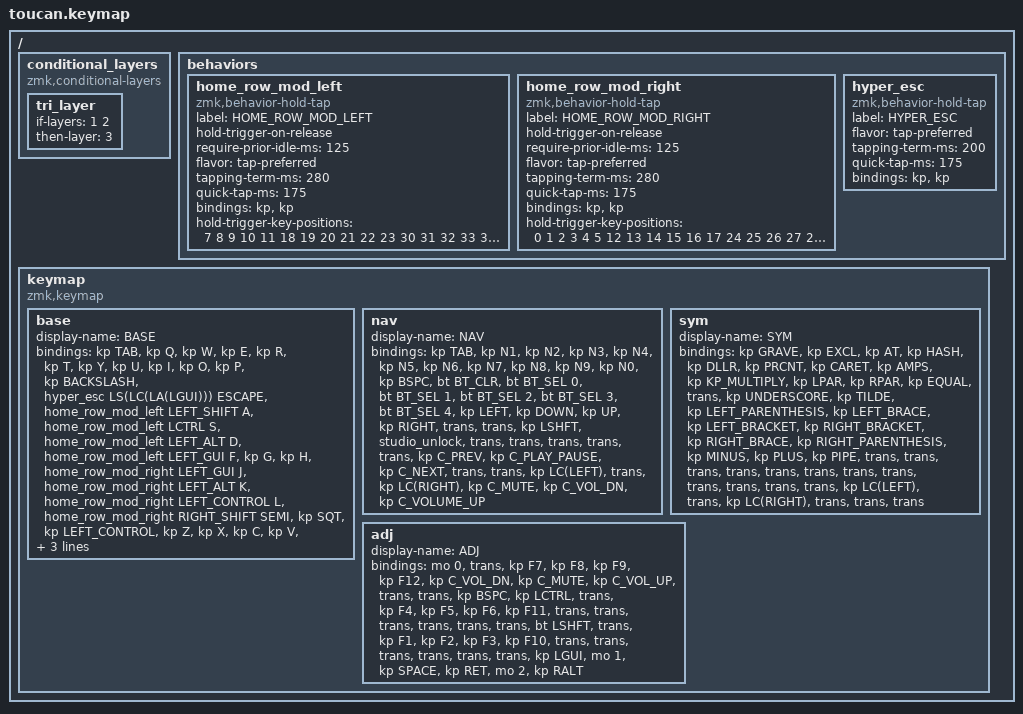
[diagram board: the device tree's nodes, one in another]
#include <behaviors.dtsi>
#include <dt-bindings/zmk/bt.h>
#include <dt-bindings/zmk/keys.h>

#define BASE 0
#define NAV  1
#define SYM  2
#define ADJ  3

/ {
    conditional_layers {
        compatible = "zmk,conditional-layers";

        tri_layer {
            if-layers = <1 2>;
            then-layer = <3>;
        };
    };

    behaviors {
        home_row_mod_left: home_row_mod_left {
            compatible = "zmk,behavior-hold-tap";
            label = "HOME_ROW_MOD_LEFT";
            #binding-cells = <2>;
            hold-trigger-on-release;
            require-prior-idle-ms = <125>;
            flavor = "tap-preferred";
            tapping-term-ms = <280>;
            quick-tap-ms = <175>;
            bindings = <&kp>, <&kp>;

            hold-trigger-key-positions = <7 8 9 10 11 18 19 20 21 22 23 30 31 32 33 34 35 40 41 39 6>;
        };

        home_row_mod_right: home_row_mod_right {
            compatible = "zmk,behavior-hold-tap";
            label = "HOME_ROW_MOD_RIGHT";
            #binding-cells = <2>;
            hold-trigger-on-release;
            require-prior-idle-ms = <125>;
            flavor = "tap-preferred";
            tapping-term-ms = <280>;
            quick-tap-ms = <175>;
            bindings = <&kp>, <&kp>;

            hold-trigger-key-positions = <0 1 2 3 4 5 12 13 14 15 16 17 24 25 26 27 28 29 36 37 38>;
        };

        hyper_esc: hyper_esc {
            compatible = "zmk,behavior-hold-tap";
            label = "HYPER_ESC";
            #binding-cells = <2>;
            flavor = "tap-preferred";
            tapping-term-ms = <200>;
            quick-tap-ms = <175>;
            bindings = <&kp>, <&kp>;
        };
    };

    keymap {
        compatible = "zmk,keymap";

        base {
            display-name = "BASE";
            bindings = <
&kp TAB  &kp Q  &kp W  &kp E  &kp R  &kp T  &kp Y  &kp U  &kp I  &kp O  &kp P  &kp BACKSLASH  &hyper_esc LS(LC(LA(LGUI))) ESCAPE  &home_row_mod_left LEFT_SHIFT A  &home_row_mod_left LCTRL S  &home_row_mod_left LEFT_ALT D  &home_row_mod_left LEFT_GUI F  &kp G  &kp H  &home_row_mod_right LEFT_GUI J  &home_row_mod_right LEFT_ALT K  &home_row_mod_right LEFT_CONTROL L  &home_row_mod_right RIGHT_SHIFT SEMI  &kp SQT  &kp LEFT_CONTROL  &kp Z  &kp X  &kp C  &kp V  &kp B  &kp N  &kp M  &kp COMMA  &kp DOT  &kp FSLH  &kp RIGHT_CONTROL  &kp BSPC  &mo 1  &kp LEFT_COMMAND  &kp RET  &mo 2  &kp SPACE
            >;
        };

        nav {
            display-name = "NAV";
            bindings = <
&kp TAB  &kp N1  &kp N2  &kp N3  &kp N4  &kp N5  &kp N6  &kp N7  &kp N8  &kp N9  &kp N0  &kp BSPC  &bt BT_CLR  &bt BT_SEL 0  &bt BT_SEL 1  &bt BT_SEL 2  &bt BT_SEL 3  &bt BT_SEL 4  &kp LEFT  &kp DOWN  &kp UP  &kp RIGHT  &trans  &trans  &kp LSHFT  &studio_unlock  &trans  &trans  &trans  &trans  &trans  &kp C_PREV  &kp C_PLAY_PAUSE  &kp C_NEXT  &trans  &trans  &kp LC(LEFT)  &trans  &kp LC(RIGHT)  &kp C_MUTE  &kp C_VOL_DN  &kp C_VOLUME_UP
            >;
        };

        sym {
            display-name = "SYM";
            bindings = <
&kp GRAVE  &kp EXCL  &kp AT  &kp HASH  &kp DLLR  &kp PRCNT  &kp CARET  &kp AMPS  &kp KP_MULTIPLY  &kp LPAR  &kp RPAR  &kp EQUAL  &trans  &kp UNDERSCORE  &kp TILDE  &kp LEFT_PARENTHESIS  &kp LEFT_BRACE  &kp LEFT_BRACKET  &kp RIGHT_BRACKET  &kp RIGHT_BRACE  &kp RIGHT_PARENTHESIS  &kp MINUS  &kp PLUS  &kp PIPE  &trans  &trans  &trans  &trans  &trans  &trans  &trans  &trans  &trans  &trans  &trans  &trans  &kp LC(LEFT)  &trans  &kp LC(RIGHT)  &trans  &trans  &trans
            >;
        };

        adj {
            display-name = "ADJ";
            bindings = <
&mo 0  &trans  &kp F7  &kp F8  &kp F9  &kp F12  &kp C_VOL_DN  &kp C_MUTE  &kp C_VOL_UP  &trans  &trans  &kp BSPC  &kp LCTRL  &trans  &kp F4  &kp F5  &kp F6  &kp F11  &trans  &trans  &trans  &trans  &trans  &trans  &bt LSHFT  &trans  &kp F1  &kp F2  &kp F3  &kp F10  &trans  &trans  &trans  &trans  &trans  &trans  &kp LGUI  &mo 1  &kp SPACE  &kp RET  &mo 2  &kp RALT
            >;
        };
    };
};
